VERSION ""

NS_ :

BS_:

BU_: XXX

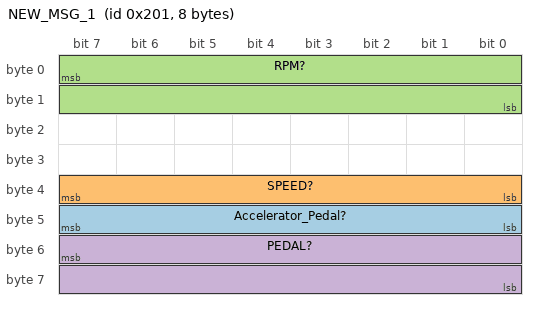
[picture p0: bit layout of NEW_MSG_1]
BO_ 513 NEW_MSG_1: 8 XXX
 SG_ Accelerator_Pedal? : 47|8@0+ (1,0) [0|255] "" XXX
 SG_ SPEED? : 39|8@0+ (1,0) [0|255] "" XXX
 SG_ RPM? : 7|16@0+ (1,0) [0|65535] "" XXX
 SG_ PEDAL? : 55|16@0+ (1,0) [0|65535] "" XXX
